AUTOSAR XML (schema 4-0-3)
standard types defined: uint8, Boolean, UInt16, UInt32, UInt8
package /AUTOSAR_Platform/DataConstrs
  range DC_Boolean: raw 0..1
  range DC_UInt16: raw 0..65535
  range DC_UInt8: raw 0..255
package /PATAC/Facility/DataTypes/Implementation
  compu method COMPU_Boolean: 0=FALSE, 1=TRUE
  unit NoUnit: factor-si-to-unit=1, offset-si-to-unit=0
package /PATAC/MSM/ComponentTypes
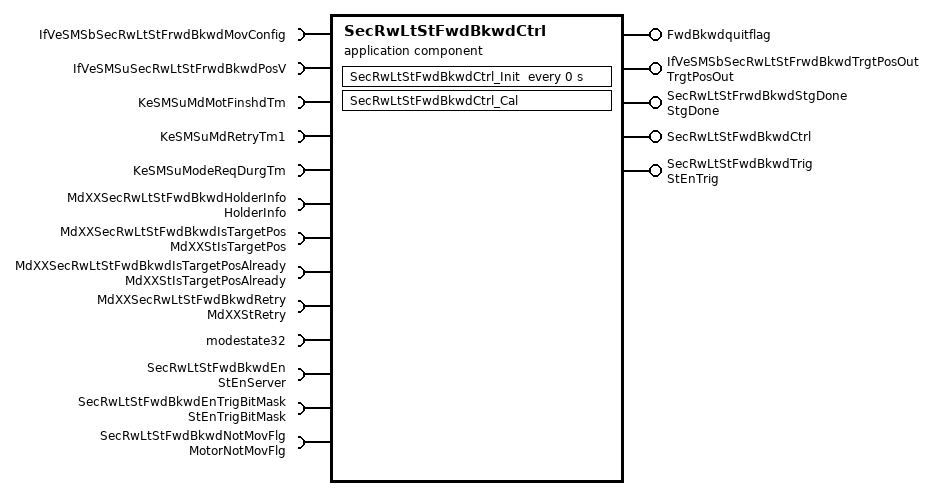
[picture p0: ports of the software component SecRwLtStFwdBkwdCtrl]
  application sw component type SecRwLtStFwdBkwdCtrl
    5 x provide port:
      FwdBkwdquitflag: nonqueued-sender-com-spec{data-element=FwdBkwdquitflag/Val, init-value=0}, provided-interface=FwdBkwdquitflag
      IfVeSMSbSecRwLtStFrwdBkwdTrgtPosOut: nonqueued-sender-com-spec{data-element=TrgtPosOut/Val, init-value=0}, provided-interface=TrgtPosOut
      SecRwLtStFrwdBkwdStgDone: nonqueued-sender-com-spec{data-element=StgDone/Val, init-value=0}, provided-interface=StgDone
      SecRwLtStFwdBkwdCtrl: server-com-spec{operation=Cal, queue-length=1}, provided-interface=SecRwLtStFwdBkwdCtrl
      SecRwLtStFwdBkwdTrig: nonqueued-sender-com-spec{data-element=StEnTrig/Val, init-value=0}, provided-interface=StEnTrig
    13 x require port:
      IfVeSMSbSecRwLtStFrwdBkwdMovConfig: nonqueued-receiver-com-spec{data-element=IfVeSMSbSecRwLtStFrwdBkwdMovConfig/Val, filter=data-filter-type=ALWAYS, init-value=0}, required-interface=IfVeSMSbSecRwLtStFrwdBkwdMovConfig
      IfVeSMSuSecRwLtStFrwdBkwdPosV: nonqueued-receiver-com-spec{data-element=IfVeSMSuSecRwLtStFrwdBkwdPosV/Val, filter=data-filter-type=ALWAYS, init-value=0}, required-interface=IfVeSMSuSecRwLtStFrwdBkwdPosV
      KeSMSuMdMotFinshdTm: parameter-require-com-spec{init-value=0, parameter=KeSMSuMdMotFinshdTm/Val}, required-interface=KeSMSuMdMotFinshdTm
      KeSMSuMdRetryTm1: parameter-require-com-spec{init-value=0, parameter=KeSMSuMdRetryTm1/Val}, required-interface=KeSMSuMdRetryTm1
      KeSMSuModeReqDurgTm: parameter-require-com-spec{init-value=0, parameter=KeSMSuModeReqDurgTm/Val}, required-interface=KeSMSuModeReqDurgTm
      MdXXSecRwLtStFwdBkwdHolderInfo: nonqueued-receiver-com-spec{data-element=HolderInfo/Val, filter=data-filter-type=ALWAYS, init-value=0}, required-interface=HolderInfo
      MdXXSecRwLtStFwdBkwdIsTargetPos: nonqueued-receiver-com-spec{data-element=MdXXStIsTargetPos/Val, filter=data-filter-type=ALWAYS, init-value=0}, required-interface=MdXXStIsTargetPos
      MdXXSecRwLtStFwdBkwdIsTargetPosAlready: nonqueued-receiver-com-spec{data-element=MdXXStIsTargetPosAlready/Val, filter=data-filter-type=ALWAYS, init-value=0}, required-interface=MdXXStIsTargetPosAlready
      MdXXSecRwLtStFwdBkwdRetry: nonqueued-receiver-com-spec{data-element=MdXXStRetry/Val, filter=data-filter-type=ALWAYS, init-value=0}, required-interface=MdXXStRetry
      modestate32: nonqueued-receiver-com-spec{data-element=modestate32/Val, filter=data-filter-type=ALWAYS, init-value=0}, required-interface=modestate32
      SecRwLtStFwdBkwdEn: required-com-specs=[Clear, Get, Set], required-interface=StEnServer
      SecRwLtStFwdBkwdEnTrigBitMask: nonqueued-receiver-com-spec{data-element=StEnTrigBitMask/Val, filter=data-filter-type=ALWAYS, init-value=0}, required-interface=StEnTrigBitMask
      SecRwLtStFwdBkwdNotMovFlg: nonqueued-receiver-com-spec{data-element=MotorNotMovFlg/Val, filter=data-filter-type=ALWAYS, init-value=0}, required-interface=MotorNotMovFlg
    behavior SecRwLtStFwdBkwdCtrl_InternalBehavior
      operation invoked event OIT_SecRwLtStFwdBkwdCtrl_Cal_SecRwLtStFwdBkwdCtrl_Cal: start-on-event=SecRwLtStFwdBkwdCtrl_Cal, operation=SecRwLtStFwdBkwdCtrl.Cal
      timing event SecRwLtStFwdBkwdCtrl_InitEvent: start-on-event=SecRwLtStFwdBkwdCtrl_Init, period=0
      runnable SecRwLtStFwdBkwdCtrl_Cal
        data-receive-point-by-arguments:
          9 x access:
            REC_IfVeSMSbSecRwLtStFrwdBkwdMovConfig_Val: accessed-variable=IfVeSMSbSecRwLtStFrwdBkwdMovConfig.Val
            REC_IfVeSMSuSecRwLtStFrwdBkwdPosV_Val: accessed-variable=IfVeSMSuSecRwLtStFrwdBkwdPosV.Val
            REC_MdXXSecRwLtStFwdBkwdHolderInfo_Val: accessed-variable=MdXXSecRwLtStFwdBkwdHolderInfo.Val
            REC_MdXXSecRwLtStFwdBkwdIsTargetPos_Val: accessed-variable=MdXXSecRwLtStFwdBkwdIsTargetPos.Val
            REC_MdXXSecRwLtStFwdBkwdIsTargetPosAlready_Val: accessed-variable=MdXXSecRwLtStFwdBkwdIsTargetPosAlready.Val
            REC_MdXXSecRwLtStFwdBkwdRetry_Val: accessed-variable=MdXXSecRwLtStFwdBkwdRetry.Val
            REC_modestate32_Val: accessed-variable=modestate32.Val
            REC_SecRwLtStFwdBkwdEnTrigBitMask_Val: accessed-variable=SecRwLtStFwdBkwdEnTrigBitMask.Val
            REC_SecRwLtStFwdBkwdNotMovFlg_Val: accessed-variable=SecRwLtStFwdBkwdNotMovFlg.Val
        data-send-points:
          4 x access:
            SEND_FwdBkwdquitflag_Val: accessed-variable=FwdBkwdquitflag.Val
            SEND_IfVeSMSbSecRwLtStFrwdBkwdTrgtPosOut_Val: accessed-variable=IfVeSMSbSecRwLtStFrwdBkwdTrgtPosOut.Val
            SEND_SecRwLtStFrwdBkwdStgDone_Val: accessed-variable=SecRwLtStFrwdBkwdStgDone.Val
            SEND_SecRwLtStFwdBkwdTrig_Val: accessed-variable=SecRwLtStFwdBkwdTrig.Val
        parameter access PA_KeSMSuMdMotFinshdTm_Val: accessed-parameter=KeSMSuMdMotFinshdTm.Val
        parameter access PA_KeSMSuMdRetryTm1_Val: accessed-parameter=KeSMSuMdRetryTm1.Val
        parameter access PA_KeSMSuModeReqDurgTm_Val: accessed-parameter=KeSMSuModeReqDurgTm.Val
        sync call SC_SecRwLtStFwdBkwdEn_Get: operation=SecRwLtStFwdBkwdEn.Get, timeout=0
      runnable SecRwLtStFwdBkwdCtrl_Init
        parameter access PA_KeSMSuMdMotFinshdTm_Val: accessed-parameter=KeSMSuMdMotFinshdTm.Val
        parameter access PA_KeSMSuMdRetryTm1_Val: accessed-parameter=KeSMSuMdRetryTm1.Val
        parameter access PA_KeSMSuModeReqDurgTm_Val: accessed-parameter=KeSMSuModeReqDurgTm.Val
  swc implementation SecRwLtStFwdBkwdCtrl_Implementation: behavior=SecRwLtStFwdBkwdCtrl_InternalBehavior
    code-descriptors:
      code Default: artifact-descriptors=autosar-engineering-object={short-label=Default, category=SWSRC}
package /PATAC/MSM/ModeAdjust/CalPortInterface
  parameter interface KeSMSuMdMotFinshdTm
    parameter data prototype Val: sw-calibration-access=READ-WRITE, type=UInt16
  parameter interface KeSMSuModeReqDurgTm
    parameter data prototype Val: sw-calibration-access=READ-WRITE, type=UInt16
package /PATAC/MSM/ModeAdjust/Interfaces
  sender receiver interface IfVeSMSuSecRwLtStFrwdBkwdPosV: invalidation-policy{data-element=IfVeSMSuSecRwLtStFrwdBkwdPosV/Val, handle-invalid=DONT-INVALIDATE}
    data Val: type=Boolean
package /PATAC/MSM/ModeAdjust/PortInterface
  client server interface SecRwLtStFwdBkwdCtrl
    operation Cal
  client server interface StEnServer
    operation Clear
      arg data: type=UInt8, direction=IN, server-argument-impl-policy=USE-ARGUMENT-TYPE
    operation Get
      arg data: type=UInt32, direction=OUT, server-argument-impl-policy=USE-ARGUMENT-TYPE
    operation Set
      arg data: type=UInt8, direction=IN, server-argument-impl-policy=USE-ARGUMENT-TYPE
  11 x sender receiver interface:
    FwdBkwdquitflag: invalidation-policy{data-element=FwdBkwdquitflag/Val, handle-invalid=DONT-INVALIDATE}
      data Val: type=Boolean
    HolderInfo: invalidation-policy{data-element=HolderInfo/Val, handle-invalid=DONT-INVALIDATE}
      data Val: type=UInt32
    MdXXStIsTargetPos: invalidation-policy{data-element=MdXXStIsTargetPos/Val, handle-invalid=DONT-INVALIDATE}
      data Val: type=UInt32
    MdXXStIsTargetPosAlready: invalidation-policy{data-element=MdXXStIsTargetPosAlready/Val, handle-invalid=DONT-INVALIDATE}
      data Val: type=UInt32
    MdXXStRetry: invalidation-policy{data-element=MdXXStRetry/Val, handle-invalid=DONT-INVALIDATE}
      data Val: type=UInt32
    modestate32: invalidation-policy{data-element=modestate32/Val, handle-invalid=DONT-INVALIDATE}
      data Val: type=UInt32
    MotorNotMovFlg: invalidation-policy{data-element=MotorNotMovFlg/Val, handle-invalid=DONT-INVALIDATE}
      data Val: type=Boolean
    StEnTrig: invalidation-policy{data-element=StEnTrig/Val, handle-invalid=DONT-INVALIDATE}
      data Val: type=Boolean
    StEnTrigBitMask: invalidation-policy{data-element=StEnTrigBitMask/Val, handle-invalid=DONT-INVALIDATE}
      data Val: type=UInt32
    StgDone: invalidation-policy{data-element=StgDone/Val, handle-invalid=DONT-INVALIDATE}
      data Val: type=Boolean
    TrgtPosOut: invalidation-policy{data-element=TrgtPosOut/Val, handle-invalid=DONT-INVALIDATE}
      data Val: type=Boolean
package /PATAC/MSM/PortInterfaces
  parameter interface KeSMSuMdRetryTm1
    parameter data prototype Val: sw-calibration-access=READ-WRITE, type=UInt8
  sender receiver interface IfVeSMSbSecRwLtStFrwdBkwdMovConfig: invalidation-policy{data-element=IfVeSMSbSecRwLtStFrwdBkwdMovConfig/Val, handle-invalid=DONT-INVALIDATE}
    data Val: type=Boolean
